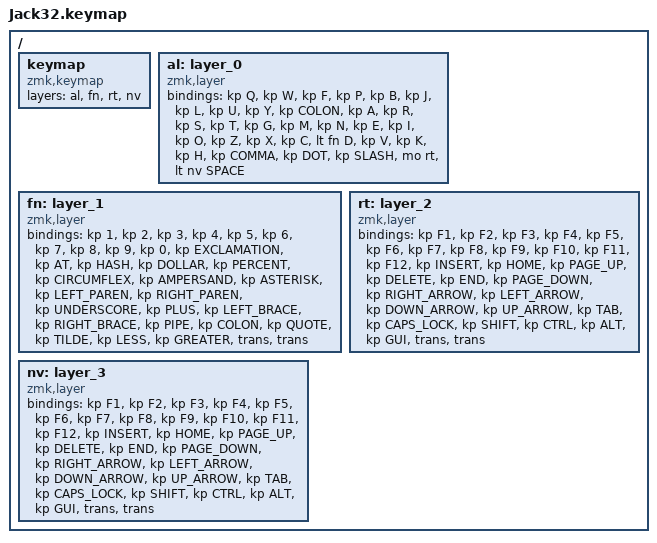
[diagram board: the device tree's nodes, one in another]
#include <behaviors.dtsi>
#include <dt-bindings/zmk/keys.h>

#include "../zmk-nodefree-config/helper.h"
#include "../zmk-nodefree-config/keypos_48keys.h"

/ {
    keymap {
        compatible = "zmk,keymap";
        layers = <
            &al
            &fn
            &rt
            &nv
        >;
    };

    al: layer_0 {
        compatible = "zmk,layer";
        bindings = <
            &kp Q  &kp W &kp F &kp P    &kp B  &kp J        &kp L &kp U     &kp Y   &kp COLON
            &kp A  &kp R &kp S &kp T    &kp G  &kp M        &kp N &kp E     &kp I   &kp O
            &kp Z  &kp X &kp C &lt fn D &kp V  &kp K        &kp H &kp COMMA &kp DOT &kp SLASH
                                        &mo rt &lt nv SPACE
        >;
    };

    fn: layer_1 {
        compatible = "zmk,layer";
        bindings = <
            &kp 1 &kp 2 &kp 3 &kp 4 &kp 5 &kp 6 &kp 7 &kp 8 &kp 9 &kp 0
            &kp EXCLAMATION &kp AT &kp HASH &kp DOLLAR &kp PERCENT &kp CIRCUMFLEX &kp AMPERSAND &kp ASTERISK &kp LEFT_PAREN &kp RIGHT_PAREN
            &kp UNDERSCORE &kp PLUS &kp LEFT_BRACE &kp RIGHT_BRACE &kp PIPE &kp COLON &kp QUOTE &kp TILDE &kp LESS &kp GREATER
            &trans &trans
        >;
    };

    rt: layer_2 {
        compatible = "zmk,layer";
        bindings = <
            &kp F1 &kp F2 &kp F3 &kp F4 &kp F5 &kp F6 &kp F7 &kp F8 &kp F9 &kp F10
            &kp F11 &kp F12 &kp INSERT &kp HOME &kp PAGE_UP &kp DELETE &kp END &kp PAGE_DOWN &kp RIGHT_ARROW &kp LEFT_ARROW
            &kp DOWN_ARROW &kp UP_ARROW &kp TAB &kp CAPS_LOCK &kp SHIFT &kp CTRL &kp ALT &kp GUI
            &trans &trans
        >;
    };

    nv: layer_3 {
        compatible = "zmk,layer";
        bindings = <
            &kp F1 &kp F2 &kp F3 &kp F4 &kp F5 &kp F6 &kp F7 &kp F8 &kp F9 &kp F10
            &kp F11 &kp F12 &kp INSERT &kp HOME &kp PAGE_UP &kp DELETE &kp END &kp PAGE_DOWN &kp RIGHT_ARROW &kp LEFT_ARROW
            &kp DOWN_ARROW &kp UP_ARROW &kp TAB &kp CAPS_LOCK &kp SHIFT &kp CTRL &kp ALT &kp GUI
            &trans &trans
        >;
    };
};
